# Polarfire SoC register map
Vendor: Microchip; File version: 1.0
CPU: Microchip PolarFire SoC 1.0, little endian
Registers are 32-bit, read-write, reset 0x0 unless marked. A register's access mark holds for its fields unless they carry their own. Offsets are from the block's base; [hi:lo] are bit positions; {n}, {i} and the like mark numbered series.

## BUS_ERROR_UNIT_H0 — MSS Bus Error Unit H0
Base 0x01700000
Same registers: BUS_ERROR_UNIT_H1 0x01701000, BUS_ERROR_UNIT_H2 0x01702000, BUS_ERROR_UNIT_H3 0x01703000, BUS_ERROR_UNIT_H4 0x01704000
0x00 CAUSE 8-bit reset not defined — Cause of error event based on mhpmevent register
0x08 VALUE 64-bit reset not defined — Physical address of the error event
0x10 ENABLE 8-bit reset not defined — Event enable mask
0x18 PLIC_INT 8-bit reset not defined — Platform level interrupt enable mask
0x20 ACCRUED 8-bit reset not defined — Accrued event mask
0x28 LOCAL_INT 8-bit reset not defined — Local interrupt enable mask

## CACHE_CTRL — Cache Controller
Base 0x02010000
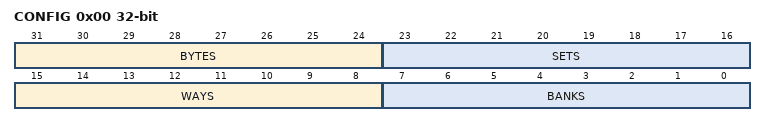
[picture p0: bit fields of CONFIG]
0x00 CONFIG ro reset not defined — Information on the configuration of the L2 cache
  [31:24] BYTES — Base-2 logarithm of the number of bytes in a cache blocks
  [23:16] SETS — Base-2 logarithm of the number of sets in a cache bank
  [15:8] WAYS — Total number of enabled ways in the cache
  [7:0] BANKS — Number of banks in the cache
0x08 WAY_ENABLE 8-bit — The WayEnable register determines which ways of the L2 cache controller are enabled as cache. Way indexes less than or equal to this register value may be used by the cache.
0x40 ECC_INJECT_ERROR reset not defined — The ECCInjectError register can be used to insert an ECC error into either the backing data or meta-data SRAM. This function can be used to test error correction logic, measurement, and recovery.
0x100 ECC_DIR_FIX_ADDR 64-bit ro reset not defined — The ECCDirFixAddr register is a Read-Only register which contains the address of the most recently corrected metadata error. This field only supplies the portions of the address which correspond to the affected set and bank, because all ways are corrected together.
0x108 ECC_DIR_FIX_COUNT ro reset not defined
0x140 ECC_DATA_FIX_ADDR 64-bit ro reset not defined
0x148 ECC_DATA_FIX_COUNT ro reset not defined
0x160 ECC_DATA_FAIL_ADDR 64-bit ro reset not defined
0x168 ECC_DATA_FAIL_COUNT ro reset not defined
0x200 FLUSH64 64-bit wo reset not defined
0x240 FLUSH32 wo reset not defined
0x800 WAY_MASK_DMA 64-bit reset not defined
{0x808+8i} WAY_MASK_AXI4_SLAVE_PORT_{i} 64-bit reset not defined (i=0..3)
0x828 WAY_MASK_E51_DCACHE 64-bit reset not defined
0x830 WAY_MASK_E51_ICACHE 64-bit reset not defined
{0x828+0x10*i} WAY_MASK_U54_{i}_DCACHE 64-bit reset not defined (i=1..4)
{0x830+0x10*i} WAY_MASK_U54_{i}_ICACHE 64-bit reset not defined (i=1..4)

## WDOG0_LO — WDOG0_LO Controller
Base 0x20001000
Same registers: WDOG1_LO 0x20101000, WDOG2_LO 0x20103000, WDOG3_LO 0x20105000, WDOG4_LO 0x20107000, WDOG0_HI 0x28001000, WDOG1_HI 0x28101000, WDOG2_HI 0x28103000, WDOG3_HI 0x28105000, WDOG4_HI 0x28107000
0x00 WDOG_REFRESH reset 0xFFFFF0
  [31:0] WDOGREFRESH — Writing pwdata=0xdeadc0de resets the watchdog timer to start counting down again when in the permitted refresh window. Writes of any other value will have no effect whilst in the permitted refresh window. Reads return the current timer value. A write to this will start the watchdog once started the watchdog cannot be stopped.
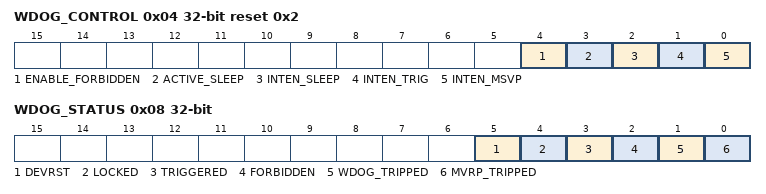
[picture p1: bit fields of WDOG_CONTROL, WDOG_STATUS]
0x04 WDOG_CONTROL reset 0x2
  [4] ENABLE_FORBIDDEN — When set if a write occurs in the forbidden region the watchdog will trigger
  [3] ACTIVE_SLEEP — When set the watchdog is operational, when the CPU is sleeping.
  [2] INTEN_SLEEP — Enables the MVRP interrupt when the MVRP level is passed and the M3 is sleeping
  [1] INTEN_TRIG — Enables the NMI interrupt when the TRIGGER level is passed. NOTE: This bit is permanently set and cannot be changed.
  [0] INTEN_MSVP — Enables the MVRP interrupt when the MVRP level is passed
0x08 WDOG_STATUS
  [5] DEVRST ro — Indicates that the DEVRST caused the NMI. Will be cleared when the system resets
  [4] LOCKED ro — Indicates that the following three registers are locked and cannot be changed
  [3] TRIGGERED ro — Indicates that the watchdog has triggered. Will be cleared when the system resets
  [2] FORBIDDEN ro — Indicates that the watchdog is currently in the forbidden range
  [1] WDOG_TRIPPED — Indicates that the TRIGGER level has passed and that the NMI is asserted, Cleared by writing a '1'
  [0] MVRP_TRIPPED — Indicates that the MVRP level has passed. Cleared by writing a '1'
0x0C WDOG_TIME reset 0xFFFFF0
  [23:0] WDOGTIME — Sets the watchdog time value. Once written locks this and the following two registers
0x10 MSVP reset 0x989680
  [23:0] WDOGMVRP — Sets the watchdog MVRP value.
0x14 TRIGGER reset 0x3E8
  [11:0] WDOGTRIG — Sets the watchdog trigger value, 0-4095 u seconds
0x18 FORCE
  [15:0] WDOGVALUE — If the watchdog has triggered writing 0x0c will cause an immediate reset, any other value or write at other times will trigger the watchdog NMI sequence.
